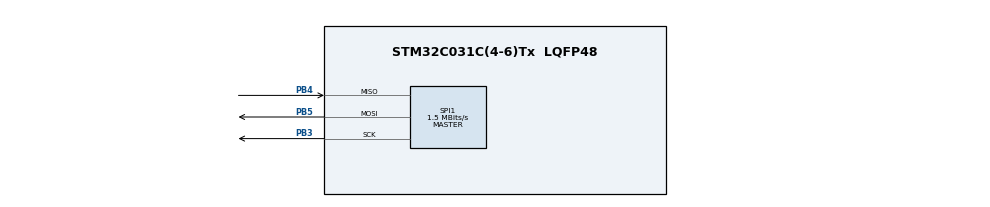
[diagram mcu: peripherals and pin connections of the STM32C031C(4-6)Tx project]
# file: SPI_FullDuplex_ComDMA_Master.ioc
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Dma.Request0=SPI1_TX
Dma.Request1=SPI1_RX
Dma.SPI1_RX.1.Direction=DMA_PERIPH_TO_MEMORY
Dma.SPI1_RX.1.EventEnable=DISABLE
Dma.SPI1_RX.1.Instance=DMA1_Channel2
Dma.SPI1_RX.1.MemDataAlignment=DMA_MDATAALIGN_BYTE
Dma.SPI1_RX.1.MemInc=DMA_MINC_ENABLE
Dma.SPI1_RX.1.Mode=DMA_NORMAL
Dma.SPI1_RX.1.PeriphDataAlignment=DMA_PDATAALIGN_BYTE
Dma.SPI1_RX.1.PeriphInc=DMA_PINC_DISABLE
Dma.SPI1_RX.1.Polarity=HAL_DMAMUX_REQ_GEN_RISING
Dma.SPI1_RX.1.Priority=DMA_PRIORITY_HIGH
Dma.SPI1_RX.1.RequestNumber=1
Dma.SPI1_RX.1.SignalID=NONE
Dma.SPI1_RX.1.SyncEnable=DISABLE
Dma.SPI1_RX.1.SyncPolarity=HAL_DMAMUX_SYNC_NO_EVENT
Dma.SPI1_RX.1.SyncRequestNumber=1
Dma.SPI1_RX.1.SyncSignalID=NONE
Dma.SPI1_TX.0.Direction=DMA_MEMORY_TO_PERIPH
Dma.SPI1_TX.0.EventEnable=DISABLE
Dma.SPI1_TX.0.Instance=DMA1_Channel3
Dma.SPI1_TX.0.MemDataAlignment=DMA_MDATAALIGN_BYTE
Dma.SPI1_TX.0.MemInc=DMA_MINC_ENABLE
Dma.SPI1_TX.0.Mode=DMA_NORMAL
Dma.SPI1_TX.0.PeriphDataAlignment=DMA_PDATAALIGN_BYTE
Dma.SPI1_TX.0.PeriphInc=DMA_PINC_DISABLE
Dma.SPI1_TX.0.Polarity=HAL_DMAMUX_REQ_GEN_RISING
Dma.SPI1_TX.0.Priority=DMA_PRIORITY_LOW
Dma.SPI1_TX.0.RequestNumber=1
Dma.SPI1_TX.0.SignalID=NONE
Dma.SPI1_TX.0.SyncEnable=DISABLE
Dma.SPI1_TX.0.SyncPolarity=HAL_DMAMUX_SYNC_NO_EVENT
Dma.SPI1_TX.0.SyncRequestNumber=1
Dma.SPI1_TX.0.SyncSignalID=NONE
Mcu.Family=STM32C0
Mcu.Name=STM32C031C(4-6)Tx
Mcu.Package=LQFP48
NVIC.DMA1_Channel2_3_IRQn=true\:0\:0\:false\:false\:true\:true\:true\:true
PB3.GPIO_PuPd=GPIO_PULLDOWN
PB3.Mode=Full_Duplex_Master
PB3.Signal=SPI1_SCK
PB4.GPIO_PuPd=GPIO_PULLDOWN
PB4.Mode=Full_Duplex_Master
PB4.Signal=SPI1_MISO
PB5.GPIO_PuPd=GPIO_PULLDOWN
PB5.Mode=Full_Duplex_Master
PB5.Signal=SPI1_MOSI
ProjectManager.HeapSize=0x200
ProjectManager.StackSize=0x400
ProjectManager.TargetToolchain=EWARM V9.20
RCC.ADCFreq_Value=48000000
RCC.AHBFreq_Value=48000000
RCC.CortexFreq_Value=48000000
RCC.EXTERNAL_CLOCK_VALUE=12288000
RCC.HCLKFreq_Value=48000000
RCC.HSE_VALUE=8000000
RCC.HSISYSCLKDivider=RCC_HSI_DIV1
RCC.HSI_VALUE=48000000
RCC.LSE_VALUE=32768
RCC.SYSCLKFreq_VALUE=48000000
SPI1.BaudRatePrescaler=SPI_BAUDRATEPRESCALER_32
SPI1.CLKPhase=SPI_PHASE_1EDGE
SPI1.CLKPolarity=SPI_POLARITY_LOW
SPI1.CRCCalculation=SPI_CRCCALCULATION_DISABLE
SPI1.CalculateBaudRate=1.5 MBits/s
SPI1.DataSize=SPI_DATASIZE_8BIT
SPI1.Direction=SPI_DIRECTION_2LINES
SPI1.FirstBit=SPI_FIRSTBIT_MSB
SPI1.GPIO_SPEED=GPIO_SPEED_FREQ_VERY_HIGH
SPI1.Mode=SPI_MODE_MASTER
SPI1.NSS=SPI_NSS_SOFT
SPI1.NSSPMode=SPI_NSS_PULSE_DISABLE
SPI1.TIMode=SPI_TIMODE_DISABLE
SPI1.VirtualType=VM_MASTER
board=custom

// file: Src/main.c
/* USER CODE BEGIN Header */
/**
  ******************************************************************************
  * @file    SPI/SPI_FullDuplex_ComDMA_Master/Src/main.c
  * @author  MCD Application Team
  * @brief   This sample code shows how to use STM32C0xx SPI HAL API to transmit
  *          and receive a data buffer with a communication process based on
  *          DMA transfer.
  *          The communication is done using 2 Boards.
  ******************************************************************************
  * @attention
  *
  * Copyright (c) 2022 STMicroelectronics.
  * All rights reserved.
  *
  * This software is licensed under terms that can be found in the LICENSE file
  * in the root directory of this software component.
  * If no LICENSE file comes with this software, it is provided AS-IS.
  *
  ******************************************************************************
  */
/* USER CODE END Header */
#include "main.h"

/* USER CODE BEGIN PD */
enum
{
  TRANSFER_WAIT,
  TRANSFER_COMPLETE,
  TRANSFER_ERROR
};
/* USER CODE END PD */

SPI_HandleTypeDef hspi1;
DMA_HandleTypeDef hdma_spi1_tx;
DMA_HandleTypeDef hdma_spi1_rx;

/* USER CODE BEGIN PV */
/* Buffer used for transmission */
uint8_t aTxBuffer[] = "****SPI - Two Boards communication based on DMA **** SPI Message ******** SPI Message ******** SPI Message ****";

/* Buffer used for reception */
uint8_t aRxBuffer[BUFFERSIZE];

/* transfer state */
__IO uint32_t wTransferState = TRANSFER_WAIT;

/* USER CODE END PV */

void SystemClock_Config(void);
static void MX_GPIO_Init(void);
static void MX_DMA_Init(void);
static void MX_SPI1_Init(void);
/* USER CODE BEGIN PFP */
static uint16_t Buffercmp(uint8_t *pBuffer1, uint8_t *pBuffer2, uint16_t BufferLength);
/* USER CODE END PFP */

int main(void)
{

  /* USER CODE BEGIN 1 */

  /* STM32C0xx HAL library initialization:
       - Configure the Flash prefetch
       - Systick timer is configured by default as source of time base, but user
         can eventually implement his proper time base source (a general purpose
         timer for example or other time source), keeping in mind that Time base
         duration should be kept 1ms since PPP_TIMEOUT_VALUEs are defined and
         handled in milliseconds basis.
       - Low Level Initialization
     */
  /* USER CODE END 1 */

  /* MCU Configuration--------------------------------------------------------*/

  /* Reset of all peripherals, Initializes the Flash interface and the Systick. */
  HAL_Init();

  /* Configure the system clock */
  SystemClock_Config();

  /* Initialize all configured peripherals */
  MX_GPIO_Init();
  MX_DMA_Init();
  MX_SPI1_Init();
  /* USER CODE BEGIN 2 */

  /* Configure LED4 */
  BSP_LED_Init(LED4);

  /* Configure User push-button button */
  BSP_PB_Init(BUTTON_USER, BUTTON_MODE_GPIO);
  /* Wait for User push-button press before starting the Communication */
  while (BSP_PB_GetState(BUTTON_USER) != GPIO_PIN_RESET)
  {
    BSP_LED_Toggle(LED4);
    HAL_Delay(100);
  }
  BSP_LED_Off(LED4);

  /*##-1- Start the Full Duplex Communication process ########################*/
  /* While the SPI in TransmitReceive process, user can transmit data through
     "aTxBuffer" buffer & receive data through "aRxBuffer" */
  if (HAL_SPI_TransmitReceive_DMA(&hspi1, (uint8_t *)aTxBuffer, (uint8_t *)aRxBuffer, BUFFERSIZE) != HAL_OK)
  {
    /* Transfer error in transmission process */
    Error_Handler();
  }

  /*##-2- Wait for the end of the transfer ###################################*/
  /*  Before starting a new communication transfer, you must wait the callback call
      to get the transfer complete confirmation or an error detection.
      For simplicity reasons, this example is just waiting till the end of the
      transfer, but application may perform other tasks while transfer operation
      is ongoing. */
  while (wTransferState == TRANSFER_WAIT)
  {
  }

  switch (wTransferState)
  {
    case TRANSFER_COMPLETE :
      /*##-3- Compare the sent and received buffers ##############################*/
      if (Buffercmp((uint8_t *)aTxBuffer, (uint8_t *)aRxBuffer, BUFFERSIZE))
      {
        /* Processing Error */
        Error_Handler();
      }
      break;
    default :
      Error_Handler();
      break;
  }

  /* USER CODE END 2 */

  /* Infinite loop */
  while (1)
  {

  }
}

void SystemClock_Config(void)
{
  RCC_OscInitTypeDef RCC_OscInitStruct = {0};
  RCC_ClkInitTypeDef RCC_ClkInitStruct = {0};

  __HAL_FLASH_SET_LATENCY(FLASH_LATENCY_1);

  /** Initializes the RCC Oscillators according to the specified parameters
  * in the RCC_OscInitTypeDef structure.
  */
  RCC_OscInitStruct.OscillatorType = RCC_OSCILLATORTYPE_HSI;
  RCC_OscInitStruct.HSIState = RCC_HSI_ON;
  RCC_OscInitStruct.HSIDiv = RCC_HSI_DIV1;
  RCC_OscInitStruct.HSICalibrationValue = RCC_HSICALIBRATION_DEFAULT;
  if (HAL_RCC_OscConfig(&RCC_OscInitStruct) != HAL_OK)
  {
    Error_Handler();
  }

  /** Initializes the CPU, AHB and APB buses clocks
  */
  RCC_ClkInitStruct.ClockType = RCC_CLOCKTYPE_HCLK|RCC_CLOCKTYPE_SYSCLK
                              |RCC_CLOCKTYPE_PCLK1;
  RCC_ClkInitStruct.SYSCLKSource = RCC_SYSCLKSOURCE_HSI;
  RCC_ClkInitStruct.SYSCLKDivider = RCC_SYSCLK_DIV1;
  RCC_ClkInitStruct.AHBCLKDivider = RCC_HCLK_DIV1;
  RCC_ClkInitStruct.APB1CLKDivider = RCC_APB1_DIV1;

  if (HAL_RCC_ClockConfig(&RCC_ClkInitStruct, FLASH_LATENCY_1) != HAL_OK)
  {
    Error_Handler();
  }
}

static void MX_SPI1_Init(void)
{

  /* SPI1 parameter configuration*/
  hspi1.Instance = SPI1;
  hspi1.Init.Mode = SPI_MODE_MASTER;
  hspi1.Init.Direction = SPI_DIRECTION_2LINES;
  hspi1.Init.DataSize = SPI_DATASIZE_8BIT;
  hspi1.Init.CLKPolarity = SPI_POLARITY_LOW;
  hspi1.Init.CLKPhase = SPI_PHASE_1EDGE;
  hspi1.Init.NSS = SPI_NSS_SOFT;
  hspi1.Init.BaudRatePrescaler = SPI_BAUDRATEPRESCALER_32;
  hspi1.Init.FirstBit = SPI_FIRSTBIT_MSB;
  hspi1.Init.TIMode = SPI_TIMODE_DISABLE;
  hspi1.Init.CRCCalculation = SPI_CRCCALCULATION_DISABLE;
  hspi1.Init.CRCPolynomial = 7;
  hspi1.Init.CRCLength = SPI_CRC_LENGTH_DATASIZE;
  hspi1.Init.NSSPMode = SPI_NSS_PULSE_DISABLE;
  if (HAL_SPI_Init(&hspi1) != HAL_OK)
  {
    Error_Handler();
  }

}

static void MX_DMA_Init(void)
{

  /* DMA controller clock enable */
  __HAL_RCC_DMA1_CLK_ENABLE();

  /* DMA interrupt init */
  /* DMA1_Channel2_3_IRQn interrupt configuration */
  HAL_NVIC_SetPriority(DMA1_Channel2_3_IRQn, 0, 0);
  HAL_NVIC_EnableIRQ(DMA1_Channel2_3_IRQn);

}

static void MX_GPIO_Init(void)
{

  /* GPIO Ports Clock Enable */
  __HAL_RCC_GPIOB_CLK_ENABLE();

}

/* USER CODE BEGIN 4 */
/**
  * @brief  TxRx Transfer completed callback.
  * @param  hspi: SPI handle
  * @note   This example shows a simple way to report end of DMA TxRx transfer, and
  *         you can add your own implementation.
  * @retval None
  */
void HAL_SPI_TxRxCpltCallback(SPI_HandleTypeDef *hspi)
{
  /* Turn LED4 on: Transfer in transmission/reception process is complete */
  BSP_LED_On(LED4);
  wTransferState = TRANSFER_COMPLETE;
}

/**
  * @brief  SPI error callbacks.
  * @param  hspi: SPI handle
  * @note   This example shows a simple way to report transfer error, and you can
  *         add your own implementation.
  * @retval None
  */
void HAL_SPI_ErrorCallback(SPI_HandleTypeDef *hspi)
{
  wTransferState = TRANSFER_ERROR;
}

/**
  * @brief  Compares two buffers.
  * @param  pBuffer1, pBuffer2: buffers to be compared.
  * @param  BufferLength: buffer's length
  * @retval 0  : pBuffer1 identical to pBuffer2
  *         >0 : pBuffer1 differs from pBuffer2
  */
static uint16_t Buffercmp(uint8_t *pBuffer1, uint8_t *pBuffer2, uint16_t BufferLength)
{
  while (BufferLength--)
  {
    if ((*pBuffer1) != *pBuffer2)
    {
      return BufferLength;
    }
    pBuffer1++;
    pBuffer2++;
  }

  return 0;
}

/* USER CODE END 4 */

void Error_Handler(void)
{
  /* USER CODE BEGIN Error_Handler_Debug */
  /* User can add his own implementation to report the HAL error return state */
  BSP_LED_Off(LED4);
  while (1)
  {
    /* Toggle LED4 for error */
    BSP_LED_Toggle(LED4);
    HAL_Delay(1000);
  }
  /* USER CODE END Error_Handler_Debug */
}
